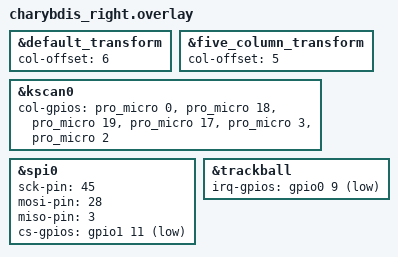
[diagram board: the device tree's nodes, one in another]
/*
 * Copyright (c) 2020 ZMK Contributors
 *
 * SPDX-License-Identifier: MIT
 */
 
#include "charybdis.dtsi"

&default_transform {
	col-offset = <6>;
};

&five_column_transform {
	col-offset = <5>;
};

&kscan0 {
	col-gpios = <&pro_micro 0 GPIO_ACTIVE_HIGH>
		, <&pro_micro 18 GPIO_ACTIVE_HIGH>
		, <&pro_micro 19 GPIO_ACTIVE_HIGH>
		, <&pro_micro 17 GPIO_ACTIVE_HIGH>
		, <&pro_micro 3 GPIO_ACTIVE_HIGH>
		, <&pro_micro 2 GPIO_ACTIVE_HIGH>
		;
};




/* Enable spi2 bus and the trackball, and define their pins */
&spi0 {
  status = "okay";
  sck-pin =  <45>;
  mosi-pin = <28>;
  miso-pin = <3>;
  cs-gpios = <&gpio1 11 GPIO_ACTIVE_LOW>;
};

&trackball {
  status = "okay";
  irq-gpios = <&gpio0 9 (GPIO_ACTIVE_LOW | GPIO_PULL_UP)>;
};
